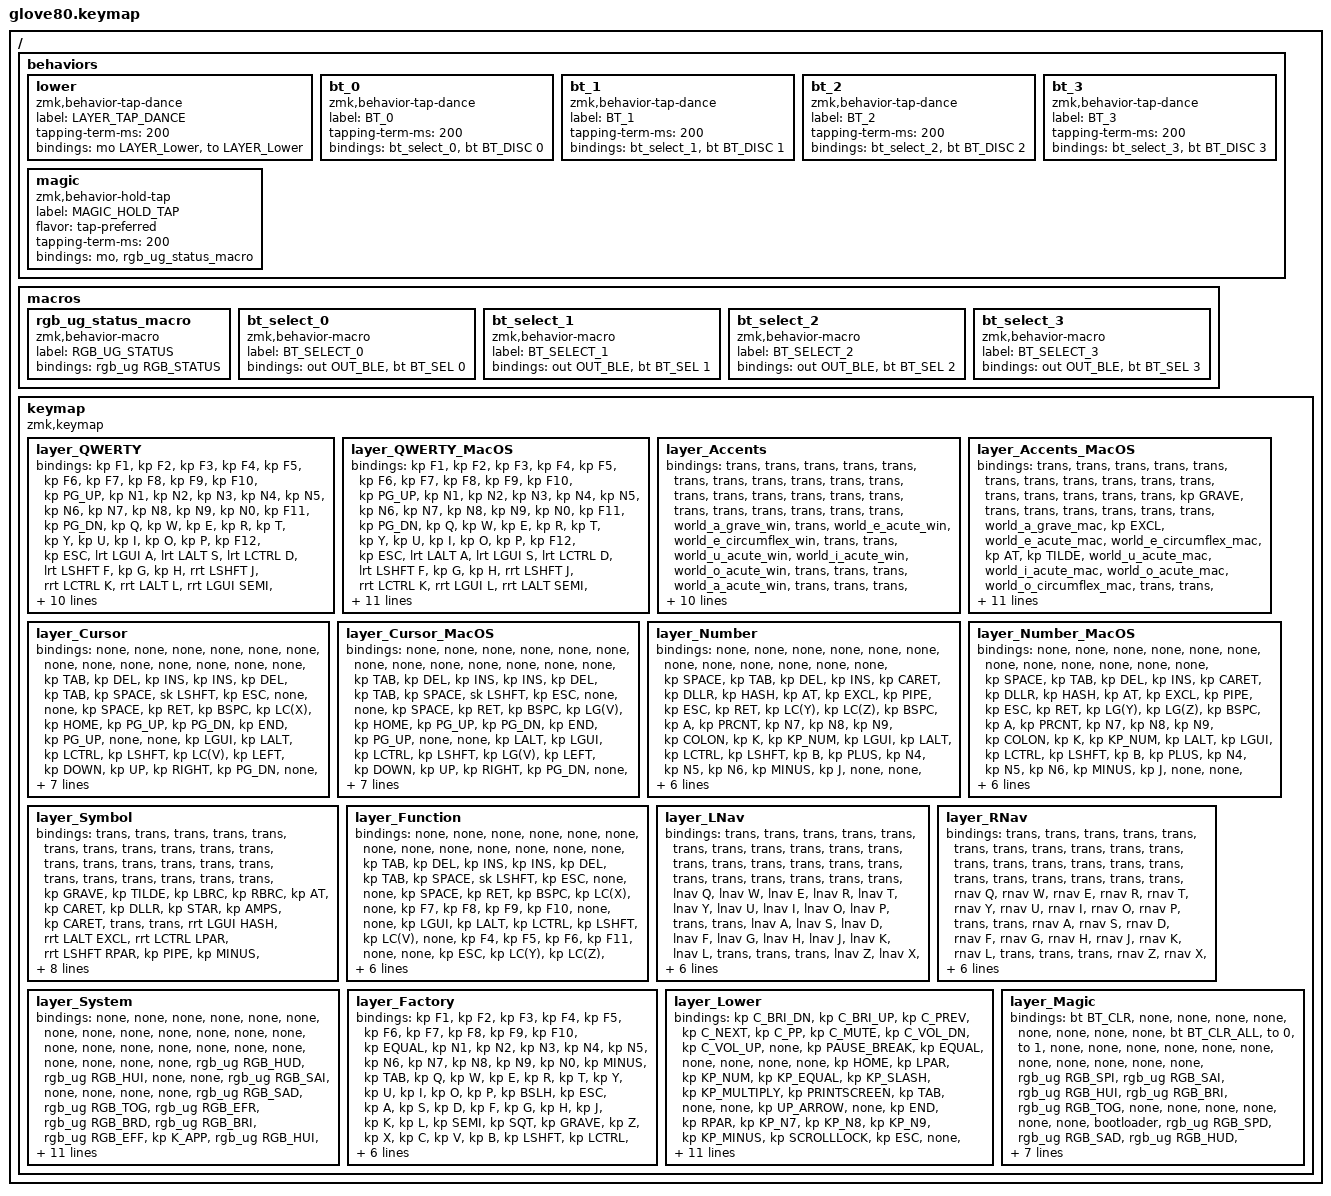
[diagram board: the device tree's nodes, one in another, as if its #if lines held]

/*
 * Copyright (c) 2020 The ZMK Contributors
 * Copyright (c) 2023 Innaworks Development Limited, trading as MoErgo
 *
 * SPDX-License-Identifier: MIT
 */


/* THIS FILE WAS GENERATED BY GLOVE80 LAYOUT EDITOR
 *
 * This file was generated automatically. You may or may not want to
 * edit it directly.
 */

#include <behaviors.dtsi>
/* Include all behavior includes needed */
#include <dt-bindings/zmk/outputs.h>
#include <dt-bindings/zmk/keys.h>
#include <dt-bindings/zmk/bt.h>
#include <dt-bindings/zmk/rgb.h>

/* Automatically generated layer name #define */
#define LAYER_QWERTY 0
#define LAYER_QWERTY_MacOS 1
#define LAYER_Accents 2
#define LAYER_Accents_MacOS 3
#define LAYER_Cursor 4
#define LAYER_Cursor_MacOS 5
#define LAYER_Number 6
#define LAYER_Number_MacOS 7
#define LAYER_Symbol 8
#define LAYER_Function 9
#define LAYER_LNav 10
#define LAYER_RNav 11
#define LAYER_System 12
#define LAYER_Factory 13
#define LAYER_Lower 14
#define LAYER_Magic 15

/* To deal with the situation where there is no Lower layer, to keep &lower happy */
#ifndef LAYER_Lower
#define LAYER_Lower 0
#endif

/* Custom Device-tree */



/* Glove80 system behavior & macros */
/ {
    behaviors {
        // For the "layer" key, it'd nice to be able to use it as either a shift or a toggle.
        // Configure it as a tap dance, so the first tap (or hold) is a &mo and the second tap is a &to
        lower: lower {
            compatible = "zmk,behavior-tap-dance";
            label = "LAYER_TAP_DANCE";
            #binding-cells = <0>;
            tapping-term-ms = <200>;
            bindings = <&mo LAYER_Lower>, <&to LAYER_Lower>;
        };
    };
};

/ {
    macros {
        rgb_ug_status_macro: rgb_ug_status_macro {
            label = "RGB_UG_STATUS";
            compatible = "zmk,behavior-macro";
            #binding-cells = <0>;
            bindings
                = <&rgb_ug RGB_STATUS>;
        };
    };
};


/ {
#ifdef BT_DISC_CMD
    behaviors {
        bt_0: bt_0 {
            compatible = "zmk,behavior-tap-dance";
            label = "BT_0";
            #binding-cells = <0>;
            tapping-term-ms = <200>;
            bindings = <&bt_select_0>, <&bt BT_DISC 0>;
        };
        bt_1: bt_1 {
            compatible = "zmk,behavior-tap-dance";
            label = "BT_1";
            #binding-cells = <0>;
            tapping-term-ms = <200>;
            bindings = <&bt_select_1>, <&bt BT_DISC 1>;
        };
        bt_2: bt_2 {
            compatible = "zmk,behavior-tap-dance";
            label = "BT_2";
            #binding-cells = <0>;
            tapping-term-ms = <200>;
            bindings = <&bt_select_2>, <&bt BT_DISC 2>;
        };
        bt_3: bt_3 {
            compatible = "zmk,behavior-tap-dance";
            label = "BT_3";
            #binding-cells = <0>;
            tapping-term-ms = <200>;
            bindings = <&bt_select_3>, <&bt BT_DISC 3>;
        };
    };
    macros {
        bt_select_0: bt_select_0 {
            label = "BT_SELECT_0";
            compatible = "zmk,behavior-macro";
            #binding-cells = <0>;
            bindings
                = <&out OUT_BLE>,
                  <&bt BT_SEL 0>;
        };
        bt_select_1: bt_select_1 {
            label = "BT_SELECT_1";
            compatible = "zmk,behavior-macro";
            #binding-cells = <0>;
            bindings
                = <&out OUT_BLE>,
                  <&bt BT_SEL 1>;
        };
        bt_select_2: bt_select_2 {
            label = "BT_SELECT_2";
            compatible = "zmk,behavior-macro";
            #binding-cells = <0>;
            bindings
                = <&out OUT_BLE>,
                  <&bt BT_SEL 2>;
        };
        bt_select_3: bt_select_3 {
            label = "BT_SELECT_3";
            compatible = "zmk,behavior-macro";
            #binding-cells = <0>;
            bindings
                = <&out OUT_BLE>,
                  <&bt BT_SEL 3>;
        };
    };
#else
    macros {
        bt_0: bt_0 {
            label = "BT_0";
            compatible = "zmk,behavior-macro";
            #binding-cells = <0>;
            bindings
                = <&out OUT_BLE>,
                  <&bt BT_SEL 0>;
        };
        bt_1: bt_1 {
            label = "BT_1";
            compatible = "zmk,behavior-macro";
            #binding-cells = <0>;
            bindings
                = <&out OUT_BLE>,
                  <&bt BT_SEL 1>;
        };
        bt_2: bt_2 {
            label = "BT_2";
            compatible = "zmk,behavior-macro";
            #binding-cells = <0>;
            bindings
                = <&out OUT_BLE>,
                  <&bt BT_SEL 2>;
        };
        bt_3: bt_3 {
            label = "BT_3";
            compatible = "zmk,behavior-macro";
            #binding-cells = <0>;
            bindings
                = <&out OUT_BLE>,
                  <&bt BT_SEL 3>;
        };
    };
#endif
};

/ {
    behaviors {
        magic: magic {
            compatible = "zmk,behavior-hold-tap";
            label = "MAGIC_HOLD_TAP";
            #binding-cells = <2>;
            flavor = "tap-preferred";
            tapping-term-ms = <200>;
            bindings = <&mo>, <&rgb_ug_status_macro>;
        };
    };
};

/* #define for key positions */
#define POS_LH_T1 52
#define POS_LH_T2 53
#define POS_LH_T3 54
#define POS_LH_T4 69
#define POS_LH_T5 70
#define POS_LH_T6 71
#define POS_LH_C1R2 15
#define POS_LH_C1R3 27
#define POS_LH_C1R4 39
#define POS_LH_C1R5 51
#define POS_LH_C2R1 4
#define POS_LH_C2R2 14
#define POS_LH_C2R3 26
#define POS_LH_C2R4 38
#define POS_LH_C2R5 50
#define POS_LH_C2R6 68
#define POS_LH_C3R1 3
#define POS_LH_C3R2 13
#define POS_LH_C3R3 25
#define POS_LH_C3R4 37
#define POS_LH_C3R5 49
#define POS_LH_C3R6 67
#define POS_LH_C4R1 2
#define POS_LH_C4R2 12
#define POS_LH_C4R3 24
#define POS_LH_C4R4 36
#define POS_LH_C4R5 48
#define POS_LH_C4R6 66
#define POS_LH_C5R1 1
#define POS_LH_C5R2 11
#define POS_LH_C5R3 23
#define POS_LH_C5R4 35
#define POS_LH_C5R5 47
#define POS_LH_C5R6 65
#define POS_LH_C6R1 0
#define POS_LH_C6R2 10
#define POS_LH_C6R3 22
#define POS_LH_C6R4 34
#define POS_LH_C6R5 46
#define POS_LH_C6R6 64
#define POS_RH_T1 57
#define POS_RH_T2 56
#define POS_RH_T3 55
#define POS_RH_T4 74
#define POS_RH_T5 73
#define POS_RH_T6 72
#define POS_RH_C1R2 16
#define POS_RH_C1R3 28
#define POS_RH_C1R4 40
#define POS_RH_C1R5 58
#define POS_RH_C2R1 5
#define POS_RH_C2R2 17
#define POS_RH_C2R3 29
#define POS_RH_C2R4 41
#define POS_RH_C2R5 59
#define POS_RH_C2R6 75
#define POS_RH_C3R1 6
#define POS_RH_C3R2 18
#define POS_RH_C3R3 30
#define POS_RH_C3R4 42
#define POS_RH_C3R5 60
#define POS_RH_C3R6 76
#define POS_RH_C4R1 7
#define POS_RH_C4R2 19
#define POS_RH_C4R3 31
#define POS_RH_C4R4 43
#define POS_RH_C4R5 61
#define POS_RH_C4R6 77
#define POS_RH_C5R1 8
#define POS_RH_C5R2 20
#define POS_RH_C5R3 32
#define POS_RH_C5R4 44
#define POS_RH_C5R5 62
#define POS_RH_C5R6 78
#define POS_RH_C6R1 9
#define POS_RH_C6R2 21
#define POS_RH_C6R3 33
#define POS_RH_C6R4 45
#define POS_RH_C6R5 63
#define POS_RH_C6R6 79

/* Custom Defined Behaviors */
/ {
#include "custom.dtsi"
};

/* Automatically generated macro definitions */
/ {
    macros {
    
    };
};

/* Automatically generated keymap */
/ {
    keymap {
        compatible = "zmk,keymap";


        layer_QWERTY {
            bindings = <
               &kp F1       &kp F2       &kp F3        &kp F4        &kp F5                                                                                                                                              &kp F6        &kp F7       &kp F8          &kp F9   &kp F10
            &kp PG_UP       &kp N1       &kp N2        &kp N3        &kp N4  &kp N5                                                                                                                       &kp N6         &kp N7        &kp N8       &kp N9          &kp N0   &kp F11
            &kp PG_DN        &kp Q        &kp W         &kp E         &kp R   &kp T                                                                                                                        &kp Y          &kp U         &kp I        &kp O           &kp P   &kp F12
              &kp ESC  &lrt LGUI A  &lrt LALT S  &lrt LCTRL D  &lrt LSHFT F   &kp G                                                                                                                        &kp H  &rrt  LSHFT J  &rrt LCTRL K  &rrt LALT L  &rrt LGUI SEMI  &kp HOME
           &caps_word        &kp Z        &kp X         &kp C         &kp V   &kp B                &kp ESC    &kp DEL               &kp ESC               &key_repeat     &mo 10                  &mo 11   &kp N          &kp M     &kp COMMA      &kp DOT        &kp FSLH   &kp END
 &magic LAYER_Magic 0    &kp LCTRL     &kp LGUI      &kp LALT         &mo 2          &lt LAYER_Number BSPC  &kp LSHFT  &lt LAYER_Cursor TAB  &lt LAYER_Function ENTER  &kp LSHFT  &lt LAYER_Symbol SPACE                  &mo 2      &kp LALT     &kp LGUI       &kp LCTRL    &lower
            >;
        };

        layer_QWERTY_MacOS {
            bindings = <
               &kp F1       &kp F2       &kp F3        &kp F4                       &kp F5                                                                                                                                                           &kp F6        &kp F7       &kp F8          &kp F9   &kp F10
            &kp PG_UP       &kp N1       &kp N2        &kp N3                       &kp N4  &kp N5                                                                                                                      &kp N6                       &kp N7        &kp N8       &kp N9          &kp N0   &kp F11
            &kp PG_DN        &kp Q        &kp W         &kp E                        &kp R   &kp T                                                                                                                       &kp Y                        &kp U         &kp I        &kp O           &kp P   &kp F12
              &kp ESC  &lrt LALT A  &lrt LGUI S  &lrt LCTRL D                 &lrt LSHFT F   &kp G                                                                                                                       &kp H                 &rrt LSHFT J  &rrt LCTRL K  &rrt LGUI L  &rrt LALT SEMI  &kp HOME
           &caps_word        &kp Z        &kp X         &kp C  &lrlt LAYER_Accents_MacOS V   &kp B                      &kp ESC     &kp DEL                     &kp ESC             &key_repeat      &mo 10     &mo 11   &kp N  &rrlt LAYER_Accents_MacOS V     &kp COMMA      &kp DOT        &kp FSLH   &kp END
 &magic LAYER_Magic 0      &kp TAB    &kp LCTRL      &kp LALT                     &kp LGUI          &lt LAYER_Number_MacOS BSPC  &one LSHFT  &lt LAYER_Cursor_MacOS TAB  &lt LAYER_Symbol ENTER  &one LSHFT  &kp SPACE                             &kp LGUI      &kp LALT    &kp LCTRL         &kp DEL    &lower
            >;
        };

        layer_Accents {
            bindings = <
 &trans                   &trans              &trans                         &trans                   &trans                                                                              &trans              &trans                   &trans  &trans  &trans
 &trans                   &trans              &trans                         &trans                   &trans  &trans                                                  &trans              &trans              &trans                   &trans  &trans  &trans
 &trans       &world_a_grave_win              &trans             &world_e_acute_win  &world_e_circumflex_win  &trans                                                  &trans  &world_u_acute_win  &world_i_acute_win       &world_o_acute_win  &trans  &trans
 &trans       &world_a_acute_win              &trans                         &trans                   &trans  &trans                                                  &trans              &trans              &trans  &world_o_circumflex_win  &trans  &trans
 &trans  &world_a_circumflex_win  &world_o_tilde_win  &world_consonants_cedilla_win       &world_a_tilde_win  &trans  &trans  &trans  &trans  &trans  &trans  &trans  &trans              &trans              &trans                   &trans  &trans  &trans
 &trans                   &trans              &trans                         &trans                   &trans          &trans  &trans  &trans  &trans  &trans  &trans                      &trans              &trans                   &trans  &trans  &trans
            >;
        };

        layer_Accents_MacOS {
            bindings = <
 &trans                   &trans              &trans                         &trans                   &trans                                                                                       &trans              &trans              &trans                   &trans  &trans
 &trans                   &trans              &trans                         &trans                   &trans    &trans                                                      &kp GRAVE              &trans              &trans              &trans                   &trans  &trans
 &trans       &world_a_grave_mac            &kp EXCL             &world_e_acute_mac  &world_e_circumflex_mac    &kp AT                                                      &kp TILDE  &world_u_acute_mac  &world_i_acute_mac  &world_o_acute_mac  &world_o_circumflex_mac  &trans
 &trans       &world_a_acute_mac           &kp QMARK                       &kp LPAR                 &kp RPAR  &kp PIPE                                                      &kp MINUS            &kp PLUS             &kp DQT             &kp SQT                &kp COLON  &trans
 &trans  &world_a_circumflex_mac  &world_o_tilde_mac  &world_consonants_cedilla_mac       &world_a_tilde_mac  &kp BSLH  &trans  &trans  &trans  &trans  &kp LBRC  &kp RBRC  &kp UNDER           &kp EQUAL              &kp LT              &kp GT                &kp QMARK  &trans
 &trans                   &trans              &trans                         &trans                   &trans            &trans  &trans  &trans  &trans    &trans    &trans                         &trans              &trans              &trans                   &trans  &trans
            >;
        };

        layer_Cursor {
            bindings = <
  &none     &none      &none      &none      &none                                                                                 &none      &none      &none      &none        &none
  &none     &none      &none    &kp TAB    &kp DEL    &kp INS                                                         &kp INS    &kp DEL    &kp TAB  &kp SPACE  &sk LSHFT      &kp ESC
  &none     &none  &kp SPACE    &kp RET   &kp BSPC  &kp LC(X)                                                        &kp HOME  &kp PG_UP  &kp PG_DN    &kp END  &kp PG_UP        &none
  &none  &kp LGUI   &kp LALT  &kp LCTRL  &kp LSHFT  &kp LC(V)                                                        &kp LEFT   &kp DOWN     &kp UP  &kp RIGHT  &kp PG_DN        &none
  &none   &kp ESC  &kp LC(Y)  &kp LC(Z)  &kp LC(A)  &kp LC(C)  &trans  &trans  &trans  &kp TAB    &trans     &trans   &kp RET   &kp BSPC  &kp LC(Z)  &kp LC(Y)  &kp K_APP  &kp LG(DOT)
  &none    &trans     &trans     &trans     &trans             &trans  &trans  &trans  &kp RET  &kp BSPC  &kp SPACE               &trans     &trans     &trans     &trans        &none
            >;
        };

        layer_Cursor_MacOS {
            bindings = <
  &none     &none      &none      &none      &none                                                                           &none      &none      &none      &none              &none
  &none     &none      &none    &kp TAB    &kp DEL    &kp INS                                                   &kp INS    &kp DEL    &kp TAB  &kp SPACE  &sk LSHFT            &kp ESC
  &none     &none  &kp SPACE    &kp RET   &kp BSPC  &kp LG(V)                                                  &kp HOME  &kp PG_UP  &kp PG_DN    &kp END  &kp PG_UP              &none
  &none  &kp LALT   &kp LGUI  &kp LCTRL  &kp LSHFT  &kp LG(V)                                                  &kp LEFT   &kp DOWN     &kp UP  &kp RIGHT  &kp PG_DN              &none
  &none   &kp ESC  &kp LG(Y)  &kp LG(Z)  &kp LG(A)  &kp LG(C)  &trans  &trans  &trans  &trans  &trans  &trans   &kp RET   &kp BSPC  &kp LG(Z)  &kp LG(Y)  &kp K_APP  &kp LC(LG(SPACE))
  &none    &trans     &trans     &trans     &trans             &trans  &trans  &trans  &trans  &trans  &trans               &trans     &trans     &trans     &trans              &none
            >;
        };

        layer_Number {
            bindings = <
      &none     &none      &none      &none      &none                                                                             &none     &none   &none      &none      &none
      &none     &none  &kp SPACE    &kp TAB    &kp DEL  &kp INS                                                      &kp CARET  &kp DLLR  &kp HASH  &kp AT   &kp EXCL   &kp PIPE
    &kp ESC   &kp RET  &kp LC(Y)  &kp LC(Z)   &kp BSPC    &kp A                                                      &kp PRCNT    &kp N7    &kp N8  &kp N9  &kp COLON      &kp K
 &kp KP_NUM  &kp LGUI   &kp LALT  &kp LCTRL  &kp LSHFT    &kp B                                                       &kp PLUS    &kp N4    &kp N5  &kp N6  &kp MINUS      &kp J
      &none     &none  &kp SPACE    &kp TAB  &kp UNDER    &kp C  &trans  &trans  &trans   &kp BSPC   &trans  &trans   &kp STAR    &kp N1    &kp N2  &kp N3   &kp FSLH  &kp LS(G)
      &none    &trans     &trans     &trans     &trans           &trans  &trans  &trans  &kp COMMA  &kp DOT  &kp N0               &trans    &trans  &trans     &trans  &kp TILDE
            >;
        };

        layer_Number_MacOS {
            bindings = <
      &none     &none      &none      &none      &none                                                                                &none     &none   &none      &none      &none
      &none     &none  &kp SPACE    &kp TAB    &kp DEL  &kp INS                                                         &kp CARET  &kp DLLR  &kp HASH  &kp AT   &kp EXCL   &kp PIPE
    &kp ESC   &kp RET  &kp LG(Y)  &kp LG(Z)   &kp BSPC    &kp A                                                         &kp PRCNT    &kp N7    &kp N8  &kp N9  &kp COLON      &kp K
 &kp KP_NUM  &kp LALT   &kp LGUI  &kp LCTRL  &kp LSHFT    &kp B                                                          &kp PLUS    &kp N4    &kp N5  &kp N6  &kp MINUS      &kp J
      &none     &none      &none      &none  &kp UNDER    &kp C  &trans  &trans  &trans     &kp LT   &kp GT  &kp EQUAL   &kp STAR    &kp N1    &kp N2  &kp N3   &kp FSLH  &kp LS(G)
      &none    &trans     &trans     &trans     &trans           &trans  &trans  &trans  &kp COMMA  &kp DOT     &kp N0               &trans    &trans  &trans     &trans  &kp TILDE
            >;
        };

        layer_Symbol {
            bindings = <
 &trans          &trans          &trans           &trans           &trans                                                                                          &trans          &trans         &trans           &trans  &trans
 &trans          &trans          &trans           &trans           &trans    &trans                                                               &trans           &trans          &trans         &trans           &trans  &trans
 &trans       &kp GRAVE       &kp TILDE         &kp LBRC         &kp RBRC    &kp AT                                                            &kp CARET         &kp DLLR        &kp STAR       &kp AMPS        &kp CARET  &trans
 &trans  &rrt LGUI HASH  &rrt LALT EXCL  &rrt LCTRL LPAR  &rrt LSHFT RPAR  &kp PIPE                                                            &kp MINUS  &rrt LSHFT PLUS  &rrt LCTRL DQT  &rrt LALT SQT  &rrt LGUI COLON  &trans
 &trans          &trans       &kp PRCNT         &kp LBKT         &kp RBKT  &kp BSLH    &trans     &trans  &kp RET  &trans  &kp LBRC  &kp RBRC  &kp UNDER        &kp EQUAL          &kp LT         &kp GT        &kp QMARK  &trans
 &trans          &trans          &trans           &trans           &trans            &kp BSPC  &kp SPACE  &kp ESC  &trans    &trans    &trans                      &trans          &trans         &trans           &trans  &trans
            >;
        };

        layer_Function {
            bindings = <
  &none     &none      &none      &none      &none                                                                                &none    &none      &none      &none        &none
  &none     &none      &none    &kp TAB    &kp DEL    &kp INS                                                          &kp INS  &kp DEL  &kp TAB  &kp SPACE  &sk LSHFT      &kp ESC
  &none     &none  &kp SPACE    &kp RET   &kp BSPC  &kp LC(X)                                                            &none   &kp F7   &kp F8     &kp F9    &kp F10        &none
  &none  &kp LGUI   &kp LALT  &kp LCTRL  &kp LSHFT  &kp LC(V)                                                            &none   &kp F4   &kp F5     &kp F6    &kp F11        &none
  &none   &kp ESC  &kp LC(Y)  &kp LC(Z)  &kp LC(A)  &kp LC(C)    &trans     &trans  &kp SPACE  &trans  &trans  &trans    &none   &kp F1   &kp F2     &kp F3    &kp F12  &kp LG(DOT)
  &none    &trans     &trans     &trans     &trans             &kp BSPC  &kp SPACE    &kp ESC  &trans  &trans  &trans            &trans   &trans     &trans     &trans        &none
            >;
        };

        layer_LNav {
            bindings = <
 &trans   &trans   &trans   &trans   &trans                                                                                &trans   &trans   &trans   &trans  &trans
 &trans   &trans   &trans   &trans   &trans   &trans                                                              &trans   &trans   &trans   &trans   &trans  &trans
 &trans  &lnav Q  &lnav W  &lnav E  &lnav R  &lnav T                                                             &lnav Y  &lnav U  &lnav I  &lnav O  &lnav P  &trans
 &trans  &lnav A  &lnav S  &lnav D  &lnav F  &lnav G                                                             &lnav H  &lnav J  &lnav K  &lnav L   &trans  &trans
 &trans  &lnav Z  &lnav X  &lnav C  &lnav V  &lnav B      &trans      &trans     &trans  &trans  &trans  &trans  &lnav N  &lnav M   &trans   &trans   &trans  &trans
 &trans   &trans   &trans   &trans   &trans           &lnav LBRC  &lnav LPAR  &kp PRCNT  &trans  &trans  &trans            &trans   &trans   &trans   &trans  &trans
            >;
        };

        layer_RNav {
            bindings = <
 &trans   &trans   &trans   &trans   &trans                                                                                &trans   &trans   &trans   &trans  &trans
 &trans   &trans   &trans   &trans   &trans   &trans                                                              &trans   &trans   &trans   &trans   &trans  &trans
 &trans  &rnav Q  &rnav W  &rnav E  &rnav R  &rnav T                                                             &rnav Y  &rnav U  &rnav I  &rnav O  &rnav P  &trans
 &trans  &rnav A  &rnav S  &rnav D  &rnav F  &rnav G                                                             &rnav H  &rnav J  &rnav K  &rnav L   &trans  &trans
 &trans  &rnav Z  &rnav X  &rnav C  &rnav V  &rnav B      &trans      &trans     &trans  &trans  &trans  &trans  &rnav N  &rnav M   &trans   &trans   &trans  &trans
 &trans   &trans   &trans   &trans   &trans           &rnav RBRC  &rnav RPAR  &kp PRCNT  &trans  &trans  &trans            &trans   &trans   &trans   &trans  &trans
            >;
        };

        layer_System {
            bindings = <
           &none            &none            &none            &none            &none                                                                                                      &none            &none            &none            &none               &none
           &none            &none            &none            &none            &none      &none                                                                          &none            &none            &none            &none            &none               &none
           &none            &none  &rgb_ug RGB_HUD  &rgb_ug RGB_HUI            &none      &none                                                                &rgb_ug RGB_SAI            &none            &none            &none            &none     &rgb_ug RGB_SAD
 &rgb_ug RGB_TOG  &rgb_ug RGB_EFR  &rgb_ug RGB_BRD  &rgb_ug RGB_BRI  &rgb_ug RGB_EFF  &kp K_APP                                                                &rgb_ug RGB_HUI        &kp K_APP            &none            &none            &none     &rgb_ug RGB_HUD
           &none  &rgb_ug RGB_SPD  &rgb_ug RGB_SAD  &rgb_ug RGB_SAI  &rgb_ug RGB_SPI      &none      &none     &none            &none   &none   &none   &none  &rgb_ug RGB_SPI  &rgb_ug RGB_TOG        &kp PSCRN         &kp SLCK  &kp PAUSE_BREAK     &rgb_ug RGB_SPD
           &none            &none            &none            &none            &none             &kp PSCRN  &kp SLCK  &kp PAUSE_BREAK   &none   &none   &none                   &rgb_ug RGB_EFF  &rgb_ug RGB_BRI  &rgb_ug RGB_BRD  &rgb_ug RGB_EFR  &linux_magic_sysrq
            >;
        };

        layer_Factory {
            bindings = <
               &kp F1    &kp F2   &kp F3    &kp F4     &kp F5                                                                                  &kp F6     &kp F7    &kp F8    &kp F9    &kp F10
            &kp EQUAL    &kp N1   &kp N2    &kp N3     &kp N4  &kp N5                                                                  &kp N6  &kp N7     &kp N8    &kp N9    &kp N0  &kp MINUS
              &kp TAB     &kp Q    &kp W     &kp E      &kp R   &kp T                                                                   &kp Y   &kp U      &kp I     &kp O     &kp P   &kp BSLH
              &kp ESC     &kp A    &kp S     &kp D      &kp F   &kp G                                                                   &kp H   &kp J      &kp K     &kp L  &kp SEMI    &kp SQT
            &kp GRAVE     &kp Z    &kp X     &kp C      &kp V   &kp B  &kp LSHFT  &kp LCTRL    &lower  &kp LGUI  &kp RCTRL  &kp RSHFT   &kp N   &kp M  &kp COMMA   &kp DOT  &kp FSLH  &kp PG_UP
 &magic LAYER_Magic 0  &kp HOME  &kp END  &kp LEFT  &kp RIGHT           &kp BSPC    &kp DEL  &kp LALT  &kp RALT    &kp RET  &kp SPACE          &kp UP   &kp DOWN  &kp LBKT  &kp RBKT  &kp PG_DN
            >;
        };

        layer_Lower {
            bindings = <
         &kp C_BRI_DN  &kp C_BRI_UP      &kp C_PREV      &kp C_NEXT         &kp C_PP                                                                          &kp C_MUTE  &kp C_VOL_DN  &kp C_VOL_UP            &none       &kp PAUSE_BREAK
            &kp EQUAL         &none           &none           &none            &none   &kp HOME                                                     &kp LPAR  &kp KP_NUM  &kp KP_EQUAL  &kp KP_SLASH  &kp KP_MULTIPLY       &kp PRINTSCREEN
              &kp TAB         &none           &none    &kp UP_ARROW            &none    &kp END                                                     &kp RPAR   &kp KP_N7     &kp KP_N8     &kp KP_N9     &kp KP_MINUS        &kp SCROLLLOCK
              &kp ESC         &none  &kp LEFT_ARROW  &kp DOWN_ARROW  &kp RIGHT_ARROW  &kp PG_UP                                                  &kp PERCENT   &kp KP_N4     &kp KP_N5     &kp KP_N6      &kp KP_PLUS            &kp KP_NUM
            &kp GRAVE     &kp K_APP           &none         &kp F11          &kp F12  &kp PG_DN  &trans  &trans   &to 0  &trans  &trans  &trans    &kp COMMA   &kp KP_N1     &kp KP_N2     &kp KP_N3     &kp KP_ENTER              &kp LALT
 &magic LAYER_Magic 0      &kp CAPS         &kp INS         &kp F11          &kp F12             &trans  &trans  &trans  &trans  &trans  &trans                &kp KP_N0     &kp KP_N0    &kp KP_DOT     &kp KP_ENTER  &magic LAYER_Magic 0
            >;
        };

        layer_Magic {
            bindings = <
  &bt BT_CLR            &none            &none            &none            &none                                                                                  &none   &none   &none   &none  &bt BT_CLR_ALL
       &to 0            &to 1            &none            &none            &none            &none                                                         &none   &none   &none   &none   &none           &none
       &none  &rgb_ug RGB_SPI  &rgb_ug RGB_SAI  &rgb_ug RGB_HUI  &rgb_ug RGB_BRI  &rgb_ug RGB_TOG                                                         &none   &none   &none   &none   &none           &none
 &bootloader  &rgb_ug RGB_SPD  &rgb_ug RGB_SAD  &rgb_ug RGB_HUD  &rgb_ug RGB_BRD  &rgb_ug RGB_EFF                                                         &none   &none   &none   &none   &none     &bootloader
  &sys_reset            &none            &none            &none            &none            &none   &bt_2   &bt_3       &tog 13   &none   &none   &none   &none   &none   &none   &none   &none      &sys_reset
       &none            &none            &none            &none            &none                    &bt_0   &bt_1  &out OUT_USB   &none   &none   &none           &none   &none   &none   &none           &none
            >;
        };

    };
};
